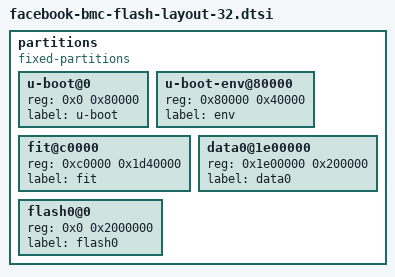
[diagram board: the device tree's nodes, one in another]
// SPDX-License-Identifier: GPL-2.0+
// Copyright (c) 2018 Facebook Inc.

partitions {
	compatible = "fixed-partitions";
	#address-cells = <1>;
	#size-cells = <1>;

	u-boot@0 {
		reg = <0x0 0x80000>;
		label = "u-boot";
	};

	u-boot-env@80000 {
		reg = <0x80000 0x40000>;
		label = "env";
	};

	fit@c0000 {
		reg = <0xc0000 0x1d40000>;
		label = "fit";
	};

	/*
	 * "data0" partition is used by several Facebook BMC platforms
	 * as persistent data store.
	 */
	data0@1e00000 {
		reg = <0x1e00000 0x200000>;
		label = "data0";
	};

	/*
	 * Although the master partition can be created by enabling
	 * MTD_PARTITIONED_MASTER option, below "flash0" partition is
	 * explicitly created to avoid breaking legacy applications.
	 */
	flash0@0 {
		reg = <0x0 0x2000000>;
		label = "flash0";
	};
};
